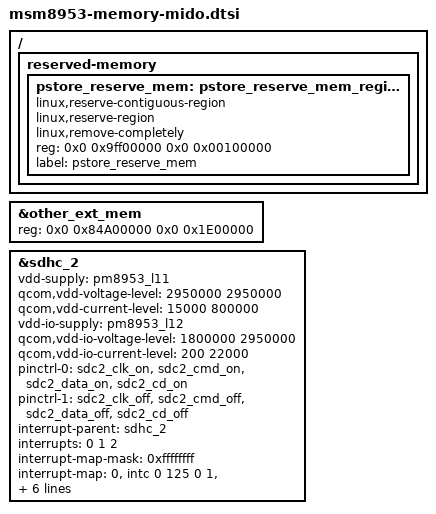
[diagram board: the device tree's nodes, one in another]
/*
 * Copyright (c) 2017, The Linux Foundation. All rights reserved.
 *
 * This program is free software; you can redistribute it and/or modify
 * it under the terms of the GNU General Public License version 2 and
 * only version 2 as published by the Free Software Foundation.
 *
 * This program is distributed in the hope that it will be useful,
 * but WITHOUT ANY WARRANTY; without even the implied warranty of
 * MERCHANTABILITY or FITNESS FOR A PARTICULAR PURPOSE.  See the
 * GNU General Public License for more details.
 */

&other_ext_mem {
    reg = <0x0 0x84A00000 0x0 0x1E00000>;
};

&sdhc_2 {
	/* device core power supply */
	vdd-supply = <&pm8953_l11>;
	qcom,vdd-voltage-level = <2950000 2950000>;
	qcom,vdd-current-level = <15000 800000>;

	/* device communication power supply */
	vdd-io-supply = <&pm8953_l12>;
	qcom,vdd-io-voltage-level = <1800000 2950000>;
	qcom,vdd-io-current-level = <200 22000>;

	pinctrl-names = "active", "sleep";
	pinctrl-0 = <&sdc2_clk_on &sdc2_cmd_on &sdc2_data_on &sdc2_cd_on>;
	pinctrl-1 = <&sdc2_clk_off &sdc2_cmd_off &sdc2_data_off &sdc2_cd_off>;

	#address-cells = <0>;
	interrupt-parent = <&sdhc_2>;
	interrupts = <0 1 2>;
	#interrupt-cells = <1>;
	interrupt-map-mask = <0xffffffff>;
	interrupt-map = <0 &intc 0 125 0
		1 &intc 0 221 0
		2 &tlmm 133 0>;
	interrupt-names = "hc_irq", "pwr_irq", "status_irq";
	cd-gpios = <&tlmm 133 0x0>;

	qcom,clk-rates = <400000 20000000 25000000 50000000 100000000
								200000000>;
	qcom,bus-speed-mode = "SDR12", "SDR25", "SDR50", "DDR50", "SDR104";

	status = "ok";
};

/ {
	reserved-memory {
		pstore_reserve_mem: pstore_reserve_mem_region@0 {
			linux,reserve-contiguous-region;
			linux,reserve-region;
			linux,remove-completely;
			reg = <0x0 0x9ff00000 0x0 0x00100000>;
			label = "pstore_reserve_mem";
		};
	};
};
